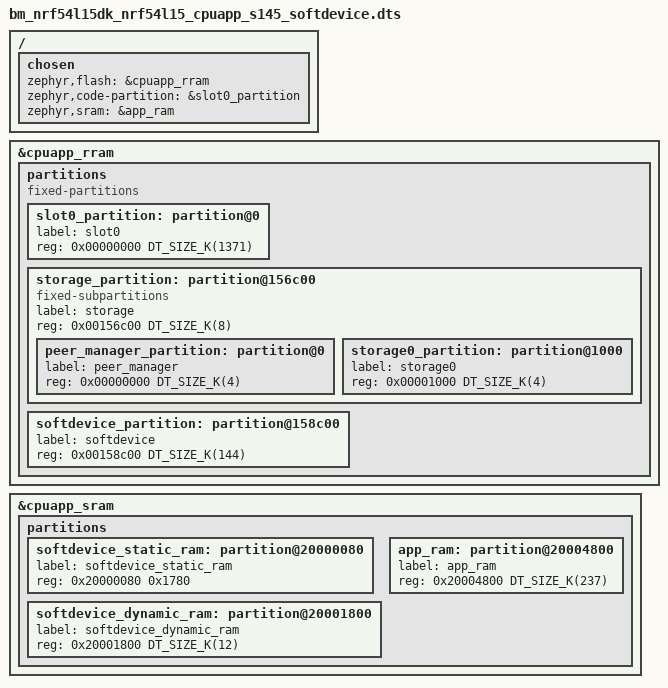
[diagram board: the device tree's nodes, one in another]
/*
 * Copyright (c) 2025 Nordic Semiconductor ASA
 *
 * SPDX-License-Identifier: LicenseRef-Nordic-5-Clause
 */

/dts-v1/;

#include <nordic/nrf54l15_cpuapp.dtsi>
#include "bm_nrf54l15dk_nrf54l15_cpuapp_common.dtsi"

/ {
	chosen {
		zephyr,flash = &cpuapp_rram;
		zephyr,code-partition = &slot0_partition;
		zephyr,sram = &app_ram;
	};
};

&cpuapp_rram {
	status = "okay";

	partitions {
		compatible = "fixed-partitions";
		#address-cells = <1>;
		#size-cells = <1>;

		slot0_partition: partition@0 {
			label = "slot0";
			reg = <0x00000000 DT_SIZE_K(1371)>;
		};

		storage_partition: partition@156c00 {
			compatible = "fixed-subpartitions";
			label = "storage";
			reg = <0x00156c00 DT_SIZE_K(8)>;
			ranges = <0x0 0x156c00 DT_SIZE_K(8)>;
			#address-cells = <1>;
			#size-cells = <1>;

			peer_manager_partition: partition@0 {
				label = "peer_manager";
				reg = <0x00000000 DT_SIZE_K(4)>;
			};

			storage0_partition: partition@1000 {
				label = "storage0";
				reg = <0x00001000 DT_SIZE_K(4)>;
			};
		};

		softdevice_partition: partition@158c00 {
			label = "softdevice";
			reg = <0x00158c00 DT_SIZE_K(144)>;
		};
	};
};

&cpuapp_sram {
	status = "okay";

	partitions {
		#address-cells = <1>;
		#size-cells = <1>;

		softdevice_static_ram: partition@20000080 {
			label = "softdevice_static_ram";
			reg = <0x20000080 0x1780>;
		};

		softdevice_dynamic_ram: partition@20001800 {
			label = "softdevice_dynamic_ram";
			reg = <0x20001800 DT_SIZE_K(12)>;
		};

		app_ram: partition@20004800 {
			label = "app_ram";
			reg = <0x20004800 DT_SIZE_K(237)>;
		};
	};
};
